# CH569 register map
Vendor: WCH Ltd.; File version: 1.0
Registers are 32-bit, read-write, reset 0x0 unless marked. A register's access mark holds for its fields unless they carry their own. Offsets are from the block's base; [hi:lo] are bit positions; {n}, {i} and the like mark numbered series.

## TMR2
Base 0x40002800
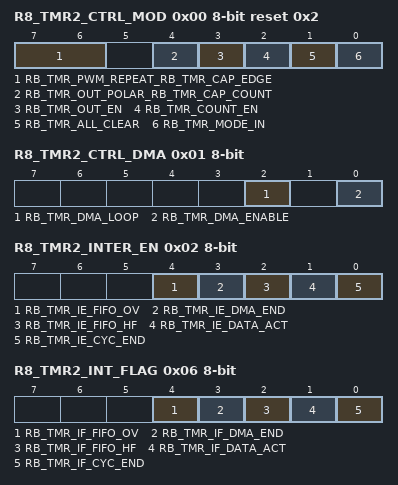
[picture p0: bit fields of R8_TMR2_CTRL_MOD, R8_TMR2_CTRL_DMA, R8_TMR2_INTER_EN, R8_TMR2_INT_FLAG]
0x00 R8_TMR2_CTRL_MOD 8-bit reset 0x2 — TMR2 mode control
  [7:6] RB_TMR_PWM_REPEAT_RB_TMR_CAP_EDGE — timer PWM repeat mode _timer capture edge mode
  [4] RB_TMR_OUT_POLAR_RB_TMR_CAP_COUNT — timer PWM output polarity _ Count sub-mode
  [3] RB_TMR_OUT_EN — timer output enable
  [2] RB_TMR_COUNT_EN — timer count enable
  [1] RB_TMR_ALL_CLEAR — force clear timer FIFO and count
  [0] RB_TMR_MODE_IN — timer in mode
0x01 R8_TMR2_CTRL_DMA 8-bit — TMR2 DMA control
  [2] RB_TMR_DMA_LOOP — timer1_2 DMA address loop enable
  [0] RB_TMR_DMA_ENABLE — timer1_2 DMA enable
0x02 R8_TMR2_INTER_EN 8-bit — TMR2 interrupt enable
  [4] RB_TMR_IE_FIFO_OV — enable interrupt for timer FIFO overflow
  [3] RB_TMR_IE_DMA_END — enable interrupt for timer1_2 DMA completion
  [2] RB_TMR_IE_FIFO_HF — enable interrupt for timer FIFO half (capture fifo >=4 or PWM fifo lower than3)
  [1] RB_TMR_IE_DATA_ACT — enable interrupt for timer capture input action or PWM trigger
  [0] RB_TMR_IE_CYC_END — enable interrupt for timer capture count timeout or PWM cycle end
0x06 R8_TMR2_INT_FLAG 8-bit — TMR2 interrupt flag
  [4] RB_TMR_IF_FIFO_OV — interrupt flag for timer FIFO overflow
  [3] RB_TMR_IF_DMA_END — interrupt flag for timer1_2 DMA completion
  [2] RB_TMR_IF_FIFO_HF — interrupt flag for timer FIFO half (capture fifo >=4 or PWM fifo lower than 3)
  [1] RB_TMR_IF_DATA_ACT — interrupt flag for timer capture input action or PWM trigger
  [0] RB_TMR_IF_CYC_END — interrupt flag for timer capture count timeout or PWM cycle end
0x07 R8_TMR2_FIFO_COUNT 8-bit ro — TMR2 FIFO count status
  [7:0] R8_TMR2_FIFO_COUNT — TMR FIFO count status
0x08 R32_TMR2_COUNT ro — TMR2 current count
  [31:0] R32_TMR2_COUNT — TMR current count
0x0C R32_TMR2_CNT_END — TMR2 end count value, only low 26 bit
  [31:0] R32_TMR2_CNT_END — TMR current count
0x10 R32_TMR2_FIFO — TMR2 end count value, only low 26 bit
  [31:0] R32_TMR2_FIFO — TMR current count
0x14 R32_TMR2_DMA_NOW — TMR2 DMA current address
  [17:0] R16_TMR2_DMA_NOW — TMR DMA current address
0x18 R32_TMR2_DMA_BEG — TMR2 DMA begin address
  [17:0] R16_TMR2_DMA_BEG
0x1C R32_TMR2_DMA_END — TMR2 DMA end address
  [17:0] R16_TMR2_DMA_END — TMR2 DMA begin address

## PWMX
Base 0x40005000
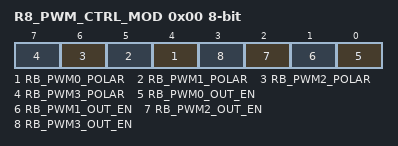
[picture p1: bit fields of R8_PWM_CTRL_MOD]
0x00 R8_PWM_CTRL_MOD 8-bit — PWM mode control
  [n+4] RB_PWM{n}_POLAR (n=0..3) — PWM{n} output polarity
  [n] RB_PWM{n}_OUT_EN (n=0..3) — PWM{n} output enable
0x01 R8_PWM_CTRL_CFG 8-bit — PWM configuration control
  [0] RB_PWM_CYCLE_SEL — PWM cycle selection
0x02 R8_PWM_CLOCK_DIV 8-bit — PWM clock divisor
0x04 R8_PWM0_DATA 8-bit — PWM data holding
  [7:0] R8_PWM0_DATA — PWM0 data holding
{0x4+i} R8_PWM{i}_DATA 8-bit (i=1..3) — PWM{i} data holding
  [{8i+7}:{8i}] R8_PWM{i}_DATA

## HSPI
Base 0x40006000
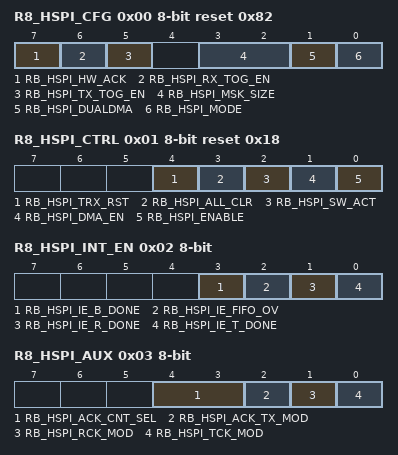
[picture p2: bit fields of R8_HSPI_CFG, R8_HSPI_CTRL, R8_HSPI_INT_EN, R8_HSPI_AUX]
0x00 R8_HSPI_CFG 8-bit reset 0x82 — parallel if tx or rx cfg
  [7] RB_HSPI_HW_ACK — parallel if tx ack by hardware
  [6] RB_HSPI_RX_TOG_EN — parallel if rx addr toggle enable
  [5] RB_HSPI_TX_TOG_EN — parallel if tx addr toggle enable
  [3:2] RB_HSPI_MSK_SIZE — parallel if data mode
  [1] RB_HSPI_DUALDMA — parallel if dualdma mode enable
  [0] RB_HSPI_MODE — parallel if mode
0x01 R8_HSPI_CTRL 8-bit reset 0x18 — parallel if tx or rx control
  [4] RB_HSPI_TRX_RST — parallel if tx and rx logic clear, high action
  [3] RB_HSPI_ALL_CLR — parallel if all clear
  [2] RB_HSPI_SW_ACT — parallel if transmit software trigger
  [1] RB_HSPI_DMA_EN — parallel if dma enable
  [0] RB_HSPI_ENABLE — parallel if enable
0x02 R8_HSPI_INT_EN 8-bit — parallel if interrupt enable register
  [3] RB_HSPI_IE_B_DONE — parallel if tx burst done interrupt enable
  [2] RB_HSPI_IE_FIFO_OV — parallel if fifo overflow interrupt enable
  [1] RB_HSPI_IE_R_DONE — parallel if receive done interrupt enable
  [0] RB_HSPI_IE_T_DONE — parallel if transmit done interrupt enable
0x03 R8_HSPI_AUX 8-bit — parallel if aux
  [4:3] RB_HSPI_ACK_CNT_SEL — delay time of parallel if send ack when receive done
  [2] RB_HSPI_ACK_TX_MOD — parallel if tx ack mode cfg
  [1] RB_HSPI_RCK_MOD — parallel if rx clk polar control
  [0] RB_HSPI_TCK_MOD — parallel if tx clk polar control
0x04 R32_HSPI_TX_ADDR0 — parallel if dma tx addr0
  [16:0] RB_HSPI_TX_ADDR0
0x08 R32_HSPI_TX_ADDR1 — parallel if dma tx addr1
  [16:0] RB_HSPI_TX_ADDR1
0x0C R32_HSPI_RX_ADDR0 — parallel if dma rx addr0
  [16:0] RB_HSPI_RX_ADDR0
0x10 R32_HSPI_RX_ADDR1 — parallel if dma rx addr1
  [16:0] RB_HSPI_RX_ADDR1
0x14 R16_HSPI_DMA_LEN0 16-bit — parallel if dma length0
  [11:0] RB_HSPI_DMA_LEN0
0x16 R16_HSPI_RX_LEN0 16-bit — parallel if receive length0
  [11:0] RB_HSPI_RX_LEN0 — parallel if dma length0
0x18 R16_HSPI_DMA_LEN1 16-bit — parallel if dma length1
  [11:0] RB_HSPI_DMA_LEN1
0x1A R16_HSPI_RX_LEN1 16-bit — parallel if receive length1
  [11:0] RB_HSPI_RX_LEN1 — parallel if dma length1
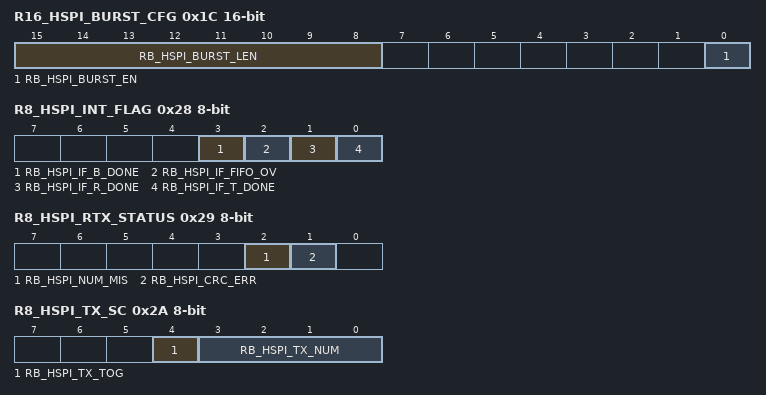
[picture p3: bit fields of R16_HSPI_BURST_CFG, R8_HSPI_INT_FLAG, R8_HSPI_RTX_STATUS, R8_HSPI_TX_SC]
0x1C R16_HSPI_BURST_CFG 16-bit — parallel if tx burst config register
  [15:8] RB_HSPI_BURST_LEN — burst transmit length
  [0] RB_HSPI_BURST_EN — burst transmit enable
0x1E R8_HSPI_BURST_CNT 8-bit — parallel if tx burst count
  [7:0] RB_HSPI_BURST_CNT
0x20 R32_HSPI_UDF0 — parallel if user defined field 0 register
  [25:0] RB_HSPI_UDF0
0x24 R32_HSPI_UDF1 — parallel if user defined field 1 register
  [25:0] RB_HSPI_UDF1
0x28 R8_HSPI_INT_FLAG 8-bit — parallel if interrupt flag
  [3] RB_HSPI_IF_B_DONE — interrupt flag for parallel if tx burst done
  [2] RB_HSPI_IF_FIFO_OV — interrupt flag for parallel if FIFO overflow
  [1] RB_HSPI_IF_R_DONE — interrupt flag for parallel if receive done
  [0] RB_HSPI_IF_T_DONE — interrupt flag for parallel if transmit done
0x29 R8_HSPI_RTX_STATUS 8-bit — parallel rtx status
  [2] RB_HSPI_NUM_MIS — rx and tx sequence number mismatch
  [1] RB_HSPI_CRC_ERR — CRC error occur
0x2A R8_HSPI_TX_SC 8-bit — parallel TX sequence ctrl
  [4] RB_HSPI_TX_TOG — parallel if tx addr toggle flag
  [3:0] RB_HSPI_TX_NUM — parallel if tx sequence num
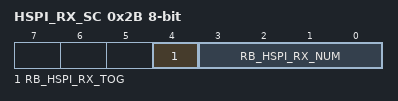
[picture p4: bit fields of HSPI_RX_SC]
0x2B HSPI_RX_SC 8-bit — parallel RX sequence ctrl
  [4] RB_HSPI_RX_TOG — parallel if rx addr toggle flag
  [3:0] RB_HSPI_RX_NUM — parallel if rx sequence num
